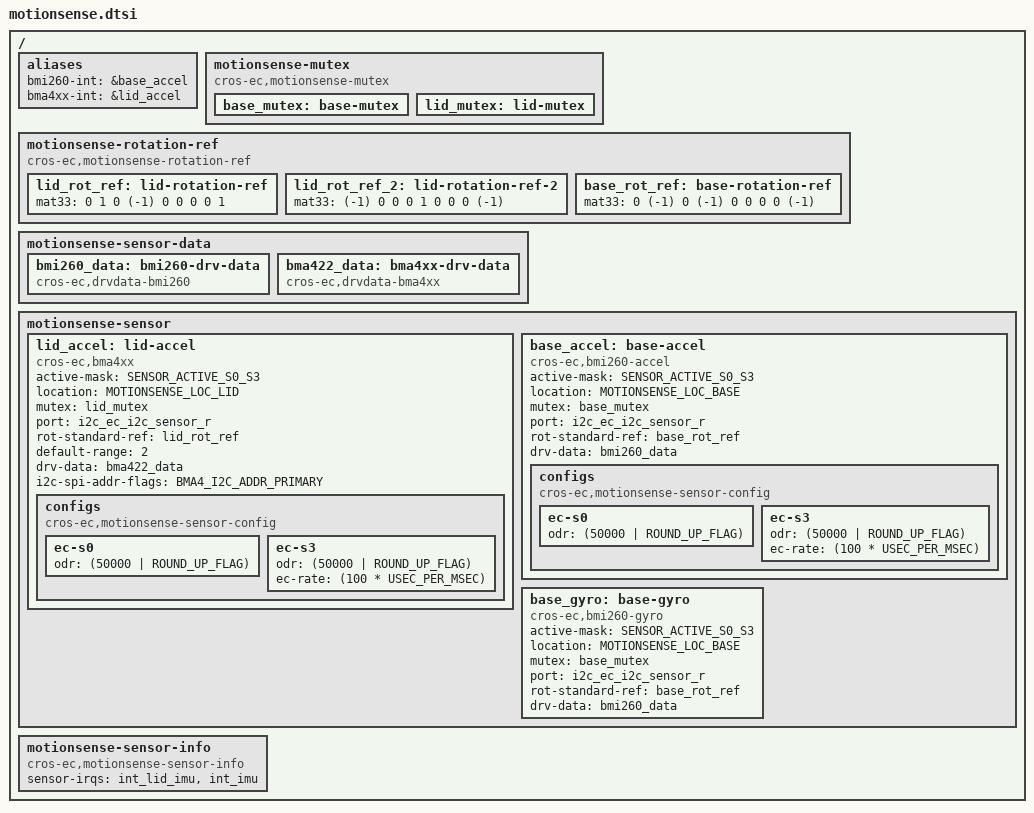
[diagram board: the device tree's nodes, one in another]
/* Copyright 2025 The ChromiumOS Authors
 * Use of this source code is governed by a BSD-style license that can be
 * found in the LICENSE file.
 */

 #include <dt-bindings/motionsense/utils.h>


/ {
	aliases {
		/*
		 * Interrupt bindings for sensor devices.
		 */
		bmi260-int = &base_accel;
		bma4xx-int = &lid_accel;
	};

	/*
	 * Declare mutexes used by sensor drivers.
	 * A mutex node is used to create an instance of mutex_t.
	 * A mutex node is referenced by a sensor node if the
	 * corresponding sensor driver needs to use the
	 * instance of the mutex.
	 */
	motionsense-mutex {
		compatible = "cros-ec,motionsense-mutex";

		base_mutex: base-mutex {
		};

		lid_mutex: lid-mutex {
		};
	};

	/* Rotation matrix used by drivers. */
	motionsense-rotation-ref {
		compatible = "cros-ec,motionsense-rotation-ref";

		lid_rot_ref: lid-rotation-ref{
			mat33 = <0 1 0
				 (-1) 0 0
				 0 0 1>;
		};

		lid_rot_ref_2: lid-rotation-ref-2{
			mat33 = <(-1) 0 0
				 0 1 0
				 0 0 (-1)>;
		};

		base_rot_ref: base-rotation-ref {
			mat33 = <0 (-1) 0
				 (-1) 0 0
				 0 0 (-1)>;
		};
	};

	/*
	 * Driver specific data. A driver-specific data can be shared with
	 * different motion sensors while they are using the same driver.
	 *
	 * If a node's compatible starts with "cros-ec,accelgyro-", it is for
	 * a common structure defined in accelgyro.h.
	 * e.g) compatible = "cros-ec,accelgyro-als-drv-data" is for
	 * "struct als_drv_data_t" in accelgyro.h
	 */
	motionsense-sensor-data {
		bmi260_data: bmi260-drv-data {
			compatible = "cros-ec,drvdata-bmi260";
			status = "okay";
		};
		bma422_data: bma4xx-drv-data {
			compatible = "cros-ec,drvdata-bma4xx";
			status = "okay";
		};
	};

	/*
	 * List of motion sensors that creates motion_sensors array.
	 * The nodelabel "lid_accel" and "base_accel" are used to indicate
	 * motion sensor IDs for lid angle calculation.
	 * TODO(b/238139272): The first entries of the array must be
	 * accelerometers,then gyroscope. Fix this dependency in the DTS
	 * processing which makes the devicetree entries independent.
	 */
	motionsense-sensor {
		lid_accel: lid-accel {
			compatible = "cros-ec,bma4xx";
			status = "okay";

			active-mask = "SENSOR_ACTIVE_S0_S3";
			location = "MOTIONSENSE_LOC_LID";
			mutex = <&lid_mutex>;
			port = <&i2c_ec_i2c_sensor_r>;
			rot-standard-ref = <&lid_rot_ref>;
			default-range = <2>;
			drv-data = <&bma422_data>;
			i2c-spi-addr-flags = "BMA4_I2C_ADDR_PRIMARY";
			configs {
				compatible =
					"cros-ec,motionsense-sensor-config";
				/* 50 Hz to support body detection. */
				ec-s0 {
					odr = <(50000 | ROUND_UP_FLAG)>;
				};
				ec-s3 {
					odr = <(50000 | ROUND_UP_FLAG)>;
					ec-rate = <(100 * USEC_PER_MSEC)>;
				};
			};
		};

		base_accel: base-accel {
			compatible = "cros-ec,bmi260-accel";
			status = "okay";

			active-mask = "SENSOR_ACTIVE_S0_S3";
			location = "MOTIONSENSE_LOC_BASE";
			mutex = <&base_mutex>;
			port = <&i2c_ec_i2c_sensor_r>;
			rot-standard-ref = <&base_rot_ref>;
			drv-data = <&bmi260_data>;
			configs {
				compatible =
					"cros-ec,motionsense-sensor-config";
				/* 50 Hz to support body detection. */
				ec-s0 {
					odr = <(50000 | ROUND_UP_FLAG)>;
				};
				ec-s3 {
					odr = <(50000 | ROUND_UP_FLAG)>;
					ec-rate = <(100 * USEC_PER_MSEC)>;
				};
			};
		};

		base_gyro: base-gyro {
			compatible = "cros-ec,bmi260-gyro";
			status = "okay";

			active-mask = "SENSOR_ACTIVE_S0_S3";
			location = "MOTIONSENSE_LOC_BASE";
			mutex = <&base_mutex>;
			port = <&i2c_ec_i2c_sensor_r>;
			rot-standard-ref = <&base_rot_ref>;
			drv-data = <&bmi260_data>;
		};
	};

	motionsense-sensor-info {
		compatible = "cros-ec,motionsense-sensor-info";

		sensor-irqs = <&int_lid_imu &int_imu>;
	};
};
